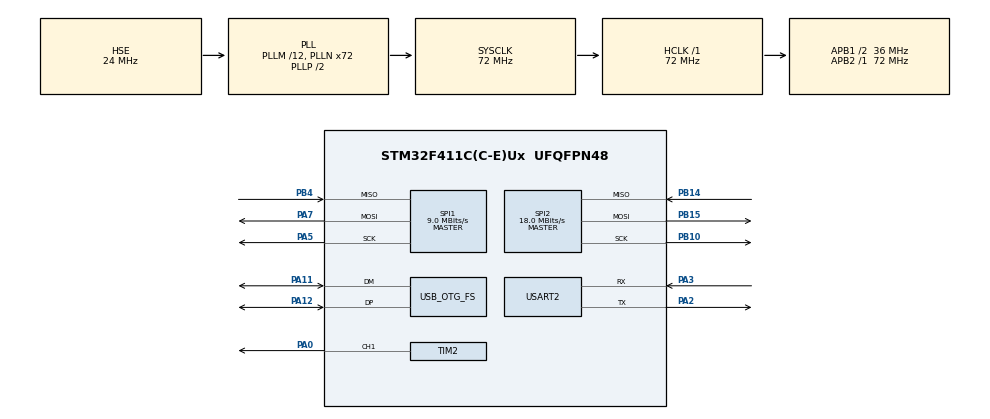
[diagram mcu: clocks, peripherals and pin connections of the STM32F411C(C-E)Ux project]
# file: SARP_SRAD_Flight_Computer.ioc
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Mcu.Family=STM32F4
Mcu.Name=STM32F411C(C-E)Ux
Mcu.Package=UFQFPN48
NVIC.OTG_FS_IRQn=true\:0\:0\:false\:false\:true\:false\:true\:true
NVIC.PriorityGroup=NVIC_PRIORITYGROUP_4
NVIC.TIM4_IRQn=true\:0\:0\:false\:false\:true\:true\:true\:true
PA0-WKUP.Signal=S_TIM2_CH1_ETR
PA11.Mode=Device_Only
PA11.Signal=USB_OTG_FS_DM
PA12.Mode=Device_Only
PA12.Signal=USB_OTG_FS_DP
PA13.Mode=Serial_Wire
PA13.Signal=SYS_JTMS-SWDIO
PA14.Mode=Serial_Wire
PA14.Signal=SYS_JTCK-SWCLK
PA2.Mode=Asynchronous
PA2.Signal=USART2_TX
PA3.Mode=Asynchronous
PA3.Signal=USART2_RX
PA5.Mode=Full_Duplex_Master
PA5.Signal=SPI1_SCK
PA7.Mode=Full_Duplex_Master
PA7.Signal=SPI1_MOSI
PB10.Mode=Full_Duplex_Master
PB10.Signal=SPI2_SCK
PB14.Mode=Full_Duplex_Master
PB14.Signal=SPI2_MISO
PB15.Mode=Full_Duplex_Master
PB15.Signal=SPI2_MOSI
PB4.Mode=Full_Duplex_Master
PB4.Signal=SPI1_MISO
PH0\ -\ OSC_IN.Mode=HSE-External-Oscillator
PH0\ -\ OSC_IN.Signal=RCC_OSC_IN
PH1\ -\ OSC_OUT.Mode=HSE-External-Oscillator
PH1\ -\ OSC_OUT.Signal=RCC_OSC_OUT
ProjectManager.HeapSize=0x200
ProjectManager.StackSize=0x400
ProjectManager.TargetToolchain=CMake
RCC.48MHZClocksFreq_Value=48000000
RCC.AHBFreq_Value=72000000
RCC.APB1CLKDivider=RCC_HCLK_DIV2
RCC.APB1Freq_Value=36000000
RCC.APB1TimFreq_Value=72000000
RCC.APB2Freq_Value=72000000
RCC.APB2TimFreq_Value=72000000
RCC.CortexFreq_Value=72000000
RCC.HCLKFreq_Value=72000000
RCC.HSE_VALUE=24000000
RCC.HSI_VALUE=16000000
RCC.LSE_VALUE=32768
RCC.PLLM=12
RCC.PLLN=72
RCC.PLLQ=3
RCC.SYSCLKFreq_VALUE=72000000
RCC.SYSCLKSource=RCC_SYSCLKSOURCE_PLLCLK
RCC.VCOOutputFreq_Value=144000000
SH.S_TIM2_CH1_ETR.0=TIM2_CH1,PWM Generation1 CH1
SPI1.BaudRatePrescaler=SPI_BAUDRATEPRESCALER_8
SPI1.CalculateBaudRate=9.0 MBits/s
SPI1.Direction=SPI_DIRECTION_2LINES
SPI1.Mode=SPI_MODE_MASTER
SPI1.VirtualType=VM_MASTER
SPI2.BaudRatePrescaler=SPI_BAUDRATEPRESCALER_2
SPI2.CalculateBaudRate=18.0 MBits/s
SPI2.Direction=SPI_DIRECTION_2LINES
SPI2.Mode=SPI_MODE_MASTER
SPI2.VirtualType=VM_MASTER
TIM2.AutoReloadPreload=TIM_AUTORELOAD_PRELOAD_ENABLE
TIM2.Channel-PWM\ Generation1\ CH1=TIM_CHANNEL_1
TIM2.Period=249
TIM2.Prescaler=71
TIM2.Pulse-PWM\ Generation1\ CH1=125
TIM4.Period=99
TIM4.Prescaler=7199
USART2.VirtualMode=VM_ASYNC
USB_DEVICE.CLASS_NAME_FS=CDC
USB_DEVICE.VirtualMode=Cdc
USB_DEVICE.VirtualModeFS=Cdc_FS
USB_OTG_FS.VirtualMode=Device_Only
VP_TIM2_VS_ClockSourceINT.Mode=Internal
VP_TIM3_VS_ClockSourceINT.Mode=Internal
VP_TIM4_VS_ClockSourceINT.Mode=Internal
VP_USB_DEVICE_VS_USB_DEVICE_CDC_FS.Mode=CDC_FS
board=custom

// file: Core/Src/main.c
/* USER CODE BEGIN Header */
/**
  ******************************************************************************
  * @file           : main.c
  * @brief          : Main program body
  ******************************************************************************
  * @attention
  *
  * Copyright (c) 2026 STMicroelectronics.
  * All rights reserved.
  *
  * This software is licensed under terms that can be found in the LICENSE file
  * in the root directory of this software component.
  * If no LICENSE file comes with this software, it is provided AS-IS.
  *
  ******************************************************************************
  */
/* USER CODE END Header */
#include "main.h"
#include "spi.h"
#include "tim.h"
#include "usart.h"
#include "usb_device.h"
#include "gpio.h"

/* USER CODE BEGIN Includes */
#include "state_machine.h"
#include "init_gpio.h"
/* USER CODE END Includes */

void SystemClock_Config(void);

int main(void)
{

  /* MCU Configuration--------------------------------------------------------*/

  /* Reset of all peripherals, Initializes the Flash interface and the Systick. */
  HAL_Init();

  /* Configure the system clock */
  SystemClock_Config();

  /* Initialize all configured peripherals */
  MX_GPIO_Init();
  MX_SPI1_Init();
  MX_SPI2_Init();
  MX_TIM2_Init();
  MX_USB_DEVICE_Init();
  MX_USART2_UART_Init();
  MX_TIM3_Init();
  MX_TIM4_Init();
  /* USER CODE BEGIN 2 */
  init_gpio();

  State curr_state = PRE_FLIGHT;
  State_Context context = {0};
  /* USER CODE END 2 */

  /* Infinite loop */
  /* USER CODE BEGIN WHILE */
  while (1)
  {
    curr_state = update_state(curr_state, &context);
    /* USER CODE END WHILE */

  }
}

void SystemClock_Config(void)
{
  RCC_OscInitTypeDef RCC_OscInitStruct = {0};
  RCC_ClkInitTypeDef RCC_ClkInitStruct = {0};

  /** Configure the main internal regulator output voltage
  */
  __HAL_RCC_PWR_CLK_ENABLE();
  __HAL_PWR_VOLTAGESCALING_CONFIG(PWR_REGULATOR_VOLTAGE_SCALE1);

  /** Initializes the RCC Oscillators according to the specified parameters
  * in the RCC_OscInitTypeDef structure.
  */
  RCC_OscInitStruct.OscillatorType = RCC_OSCILLATORTYPE_HSE;
  RCC_OscInitStruct.HSEState = RCC_HSE_ON;
  RCC_OscInitStruct.PLL.PLLState = RCC_PLL_ON;
  RCC_OscInitStruct.PLL.PLLSource = RCC_PLLSOURCE_HSE;
  RCC_OscInitStruct.PLL.PLLM = 12;
  RCC_OscInitStruct.PLL.PLLN = 72;
  RCC_OscInitStruct.PLL.PLLP = RCC_PLLP_DIV2;
  RCC_OscInitStruct.PLL.PLLQ = 3;
  if (HAL_RCC_OscConfig(&RCC_OscInitStruct) != HAL_OK)
  {
    Error_Handler();
  }

  /** Initializes the CPU, AHB and APB buses clocks
  */
  RCC_ClkInitStruct.ClockType = RCC_CLOCKTYPE_HCLK|RCC_CLOCKTYPE_SYSCLK
                              |RCC_CLOCKTYPE_PCLK1|RCC_CLOCKTYPE_PCLK2;
  RCC_ClkInitStruct.SYSCLKSource = RCC_SYSCLKSOURCE_PLLCLK;
  RCC_ClkInitStruct.AHBCLKDivider = RCC_SYSCLK_DIV1;
  RCC_ClkInitStruct.APB1CLKDivider = RCC_HCLK_DIV2;
  RCC_ClkInitStruct.APB2CLKDivider = RCC_HCLK_DIV1;

  if (HAL_RCC_ClockConfig(&RCC_ClkInitStruct, FLASH_LATENCY_2) != HAL_OK)
  {
    Error_Handler();
  }
}

void Error_Handler(void)
{
  __disable_irq();
  while (1)
  {
  }
}
